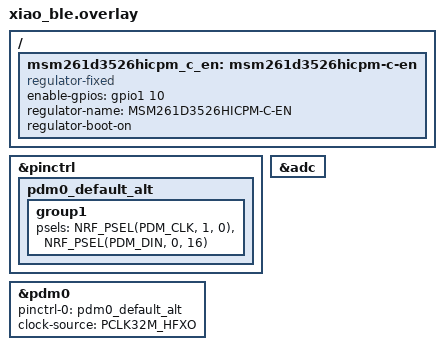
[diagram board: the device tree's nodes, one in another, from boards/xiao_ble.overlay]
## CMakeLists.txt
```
# Helix-Mic Firmware - BLE Audio Streamer for XIAO nRF52840 Sense
cmake_minimum_required(VERSION 3.20.0)

find_package(Zephyr REQUIRED HINTS $ENV{ZEPHYR_BASE})
project(helix-mic)

target_sources(app PRIVATE
    src/main.c
    src/mic.c
    src/transport.c
    src/led.c
)

target_include_directories(app PRIVATE src)
```

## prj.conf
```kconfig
# Helix-Mic Configuration

# Main config — increased for BLE stability
CONFIG_MAIN_STACK_SIZE=4096
CONFIG_SYSTEM_WORKQUEUE_STACK_SIZE=4096

# Bluetooth
CONFIG_BT=y
CONFIG_BT_PERIPHERAL=y
CONFIG_BT_DEVICE_NAME="Helix-Mic"
CONFIG_BT_DEVICE_NAME_DYNAMIC=y
CONFIG_BT_MAX_CONN=1
CONFIG_BT_L2CAP_TX_BUF_COUNT=16
CONFIG_BT_BUF_ACL_TX_SIZE=251
CONFIG_BT_BUF_ACL_RX_SIZE=251
CONFIG_BT_CONN_TX_MAX=16

# BLE stack
CONFIG_BT_RX_STACK_SIZE=4096

# BLE GATT
CONFIG_BT_GATT_DYNAMIC_DB=y
CONFIG_BT_L2CAP_TX_MTU=247

# BLE Security — encrypted link required for audio/battery access
CONFIG_BT_SMP=y
CONFIG_BT_CTLR_DATA_LENGTH_MAX=251
CONFIG_BT_CTLR_PHY_2M=y

# Audio - Zephyr DMIC API (nRF PDM driver)
CONFIG_AUDIO=y
CONFIG_AUDIO_DMIC=y
CONFIG_NRFX_PDM=y

# ADC for battery
CONFIG_ADC=y
CONFIG_ADC_NRFX_SAADC=y

# GPIO for LEDs
CONFIG_GPIO=y

# Logging over USB CDC ACM (board has zephyr,cdc-acm-uart node)
CONFIG_LOG=y
CONFIG_LOG_DEFAULT_LEVEL=3
CONFIG_LOG_MODE_IMMEDIATE=y
CONFIG_CONSOLE=y
CONFIG_PRINTK=y
CONFIG_SERIAL=y
CONFIG_UART_CONSOLE=y
CONFIG_UART_LINE_CTRL=y
CONFIG_LOG_BACKEND_UART=y
CONFIG_USE_SEGGER_RTT=n
CONFIG_LOG_BACKEND_RTT=n

# Ring buffer for audio pipeline
CONFIG_RING_BUFFER=y

# Heap for audio buffers
CONFIG_HEAP_MEM_POOL_SIZE=8192

# Clock
CONFIG_CLOCK_CONTROL_NRF=y

# Power management
CONFIG_PM_DEVICE=y
CONFIG_PM_DEVICE_RUNTIME=y

# Debug
CONFIG_DEBUG_THREAD_INFO=y
CONFIG_THREAD_NAME=y

# Newlib for memcpy etc
CONFIG_NEWLIB_LIBC=y
CONFIG_NEWLIB_LIBC_NANO=n
```

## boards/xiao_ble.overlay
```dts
/* XIAO nRF52840 Sense overlay for Helix-Mic — Zephyr DMIC API */
/* PDM pins per Seeed variant.cpp: CLK=P1.0, DATA=P0.16, PWR=P1.10 */

#include <zephyr/dt-bindings/gpio/gpio.h>

/ {
	msm261d3526hicpm_c_en: msm261d3526hicpm-c-en {
		compatible = "regulator-fixed";
		enable-gpios = <&gpio1 10 GPIO_ACTIVE_HIGH>;
		regulator-name = "MSM261D3526HICPM-C-EN";
		regulator-boot-on;
	};


};

&pinctrl {
	pdm0_default_alt: pdm0_default_alt {
		group1 {
			psels = <NRF_PSEL(PDM_CLK, 1, 0)>,   /* P1.0 = D20 = PDM_CLK */
				<NRF_PSEL(PDM_DIN, 0, 16)>;  /* P0.16 = D21 = PDM_DATA */
		};
	};
};

dmic_dev: &pdm0 {
	status = "okay";
	pinctrl-0 = <&pdm0_default_alt>;
	pinctrl-names = "default";
	clock-source = "PCLK32M_HFXO";
};

&adc {
	status = "okay";
};
```

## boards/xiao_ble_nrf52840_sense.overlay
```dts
/* XIAO nRF52840 Sense overlay for Helix-Mic — NCS v3.2.4 / Zephyr 4.x */
/* Board DTS already sets correct PDM pins (CLK=P1.0, DIN=P0.16) and pinctrl. */

#include <zephyr/dt-bindings/gpio/gpio.h>
#include <zephyr/dt-bindings/adc/adc.h>
#include <zephyr/dt-bindings/adc/nrf-saadc.h>

/ {
	msm261d3526hicpm_c_en: msm261d3526hicpm-c-en {
		compatible = "regulator-fixed";
		enable-gpios = <&gpio1 10 GPIO_ACTIVE_HIGH>;
		regulator-name = "MSM261D3526HICPM-C-EN";
		regulator-boot-on;
	};
};

dmic_dev: &pdm0 {
	status = "okay";
	clock-source = "PCLK32M_HFXO";
};

&adc {
	status = "okay";
	/delete-property/ zephyr,pm-device-runtime-auto;
};
```

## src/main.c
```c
/*
 * Helix-Mic - Main Entry Point
 * 
 * BLE audio streamer for XIAO nRF52840 Sense
 * - PDM mic capture at 16kHz 16-bit mono
 * - Raw PCM streaming over BLE (Opus fallback)
 * - Battery reporting
 */

#include <zephyr/logging/log.h>
LOG_MODULE_REGISTER(main, CONFIG_LOG_DEFAULT_LEVEL);

#include <zephyr/kernel.h>
#include <zephyr/device.h>
#include <zephyr/drivers/adc.h>
#include <zephyr/drivers/gpio.h>
#include <zephyr/devicetree.h>
#include <zephyr/dt-bindings/adc/nrf-saadc.h>
#include <zephyr/sys/ring_buffer.h>

#include "mic.h"
#include "transport.h"
#include "led.h"

/* ─── Battery ADC (matches Tjoms99/xiao_sense_nrf52840_battery_lib) ─── */
#define BATTERY_ADC_CHANNEL  7
#define BATTERY_ADC_GAIN     ADC_GAIN_1_6    /* 0.6V ref × 6 = 3.6V range */
#define BATTERY_ADC_REF      ADC_REF_INTERNAL
#define BATTERY_ADC_RES      12
#define BATTERY_R1           1037  /* kΩ (calibrated from nominal 1MΩ) */
#define BATTERY_R2           510   /* kΩ */
#define BATTERY_MIN_MV       3300
#define BATTERY_MAX_MV       4200

static const struct device *adc_dev = DEVICE_DT_GET(DT_NODELABEL(adc));

/* P0.14 read-enable: ACTIVE_LOW per Seeed schematic */
static const struct gpio_dt_spec bat_read_en = {
    .port = DEVICE_DT_GET(DT_NODELABEL(gpio0)),
    .pin = 14,
    .dt_flags = GPIO_ACTIVE_LOW,
};

static struct adc_channel_cfg adc_cfg = {
    .gain             = BATTERY_ADC_GAIN,
    .reference        = BATTERY_ADC_REF,
    .acquisition_time = ADC_ACQ_TIME(ADC_ACQ_TIME_MICROSECONDS, 40),
    .channel_id       = BATTERY_ADC_CHANNEL,
#if defined(CONFIG_ADC_NRFX_SAADC)
    .input_positive   = NRF_SAADC_AIN7,
#endif
};

static int16_t adc_buffer;
static struct adc_sequence adc_seq = {
    .channels    = BIT(BATTERY_ADC_CHANNEL),
    .buffer      = &adc_buffer,
    .buffer_size = sizeof(adc_buffer),
    .resolution  = BATTERY_ADC_RES,
};

/* Forward declarations */
static void audio_frame_handler(int16_t *buf, size_t num_samples);
static void connection_changed(bool connected);
static void on_connect_start_mic(void);
static int init_battery_adc(void);
/* Reads the battery: returns percent (0-100) or 0xFF on failure.
 * Writes the measured millivolts into *out_mv on success (0 on failure). */
static uint8_t read_battery_level(uint16_t *out_mv);

/* Track mic state for fallback start */
static volatile bool mic_running = false;

/* Ring buffer for decoupling PDM callback from BLE sends */
#define RING_BUF_PACKETS 16  /* ~1.6s buffer at 100ms frames */
#define PCM_FRAME_BYTES  (1600 * sizeof(int16_t))  /* 3200 bytes per 100ms frame */

static uint8_t ring_buf_data[RING_BUF_PACKETS * PCM_FRAME_BYTES];
static struct ring_buf audio_ring_buf;

/* Pusher thread — drains ring buffer into BLE notifications */
K_THREAD_STACK_DEFINE(pusher_stack, 4096);
static struct k_thread pusher_thread;

static uint16_t pusher_seq = 0;
#define CHUNK_SIZE 240

static void pusher_entry(void *p1, void *p2, void *p3)
{
    ARG_UNUSED(p1);
    ARG_UNUSED(p2);
    ARG_UNUSED(p3);

    uint8_t chunk[CHUNK_SIZE];

    while (1) {
        if (!transport_is_connected() || ring_buf_size_get(&audio_ring_buf) == 0) {
            k_sleep(K_MSEC(5));
            continue;
        }

        size_t got = ring_buf_get(&audio_ring_buf, chunk, CHUNK_SIZE);
        if (got > 0) {
            int ret;
            int retries = 0;
            do {
                ret = transport_send_audio(chunk, got, pusher_seq, 0x01);
                if (ret == -ENOBUFS || ret == -ENOMEM) {
                    k_sleep(K_MSEC(2));
                    retries++;
                }
            } while ((ret == -ENOBUFS || ret == -ENOMEM) && retries < 20);

            if (ret == 0) {
                pusher_seq++;
                if (pusher_seq % 500 == 1) {
                    LOG_INF("Audio pusher: sent %u packets, ring=%u",
                            pusher_seq, ring_buf_size_get(&audio_ring_buf));
                }
                /* Pace: ~7ms between 240-byte chunks = ~140 chunks/sec
                 * 13 chunks per 100ms frame = exactly real-time */
                k_sleep(K_MSEC(7));
            } else if (pusher_seq < 5) {
                LOG_WRN("Audio send failed: %d (seq=%u)", ret, pusher_seq);
            }
        }
    }
}

/* Main thread */
int main(void)
{
    int ret;
    
    LOG_INF("Helix-Mic starting...");
    
    /* Initialize LED first for boot indication */
    ret = led_init();
    if (ret < 0) {
        LOG_WRN("LED init failed: %d", ret);
    } else {
        led_set_state(LED_STATE_BOOT);
    }
    
    /* Initialize subsystems */
    ret = mic_init();
    if (ret < 0) {
        LOG_ERR("Mic init failed: %d", ret);
        return ret;
    }
    

    
    ret = transport_init();
    if (ret < 0) {
        LOG_ERR("Transport init failed: %d", ret);
        return ret;
    }
    
    ret = init_battery_adc();
    if (ret < 0) {
        LOG_WRN("Battery ADC init failed: %d", ret);
    }
    
    /* Initialize audio ring buffer and pusher thread */
    ring_buf_init(&audio_ring_buf, sizeof(ring_buf_data), ring_buf_data);
    k_thread_create(&pusher_thread, pusher_stack,
                    K_THREAD_STACK_SIZEOF(pusher_stack),
                    pusher_entry, NULL, NULL, NULL,
                    K_PRIO_PREEMPT(7), 0, K_NO_WAIT);
    k_thread_name_set(&pusher_thread, "pusher");

    /* Set callbacks */
    mic_set_frame_callback(audio_frame_handler);
    transport_set_conn_callback(connection_changed);
    transport_set_mic_start(on_connect_start_mic);
    
    /* Start BLE advertising */
    ret = transport_start_advertising();
    if (ret < 0) {
        LOG_ERR("Advertising start failed: %d", ret);
        return ret;
    }
    
    /* Boot blinks should be done by now, switch to advertising */
    led_set_state(LED_STATE_ADVERTISING);
    
    LOG_INF("Helix-Mic ready - waiting for connection");
    
    /* Main loop: poll battery every 5s while connected. LED state transitions
     * are handled directly by connection_changed() callbacks. The regular
     * battery notification also serves as a BLE link keepalive when no
     * audio is streaming. */
    while (1) {
        if (transport_is_connected()) {
            uint16_t mv = 0;
            uint8_t level = read_battery_level(&mv);
            transport_update_battery(level, mv);
            if (level == 0xFF) {
                LOG_WRN("Battery read failed");
            } else {
                LOG_INF("Battery: %u%% (%u mV)", level, mv);
            }
        }
        k_sleep(K_SECONDS(5));
    }
    
    return 0;
}

static void audio_frame_handler(int16_t *buf, size_t num_samples)
{
    if (!transport_is_connected()) {
        return;
    }

    led_notify_audio();

    size_t bytes = num_samples * sizeof(int16_t);
    int written = ring_buf_put(&audio_ring_buf, (uint8_t *)buf, bytes);
    if (written != (int)bytes) {
        LOG_WRN("Ring buf full, dropped %zu bytes", bytes - (size_t)written);
    }
}

static void on_connect_start_mic(void)
{
    int ret;
    
    if (mic_running) {
        LOG_INF("Mic already running, skipping start");
        return;
    }
    
    LOG_INF("Starting audio stream...");
    ret = mic_start();
    if (ret < 0) {
        LOG_ERR("=== MIC START FAILED === error code: %d", ret);
        switch (ret) {
        case -ENODEV:
            LOG_ERR("  Reason: PDM device not found/not ready");
            break;
        case -EINVAL:
            LOG_ERR("  Reason: Invalid PDM configuration");
            break;
        case -EIO:
            LOG_ERR("  Reason: I/O error during PDM start");
            break;
        case -EBUSY:
            LOG_ERR("  Reason: PDM device busy");
            break;
        default:
            LOG_ERR("  Reason: Unknown (check nrfx_pdm error codes)");
            break;
        }
    } else {
        mic_running = true;
        LOG_INF("Mic started successfully");
    }
}

/* Delayed work to set LED to ADVERTISING after the red disconnect flash. */
static void led_advertising_work_handler(struct k_work *work)
{
    led_set_state(LED_STATE_ADVERTISING);
}
static K_WORK_DELAYABLE_DEFINE(led_advertising_work, led_advertising_work_handler);

static void connection_changed(bool connected)
{
    if (connected) {
        LOG_INF("=== CONNECTION ESTABLISHED ===");
        /* Cancel any pending advertising-LED transition from a previous disconnect */
        k_work_cancel_delayable(&led_advertising_work);
        led_set_state(LED_STATE_CONNECTED_IDLE);
    } else {
        LOG_INF("=== CLIENT DISCONNECTED === stopping audio stream");
        /* Only run the full teardown once — this callback can fire twice
         * (once from audio_ccc_changed on unsubscribe, once from the BT
         * disconnected() callback). */
        if (!mic_running) {
            LOG_INF("connection_changed(false) — already torn down, skipping");
            /* Still ensure LED is advertising even if we skip teardown */
            k_work_reschedule(&led_advertising_work, K_MSEC(250));
            return;
        }
        int ret = mic_stop();
        if (ret < 0) {
            LOG_ERR("Mic stop failed: %d", ret);
        } else {
            LOG_INF("Mic stopped cleanly");
        }
        mic_running = false;

        /* Flush stale audio from the ring buffer so the next connection
         * doesn't start with leftover data from the previous session. */
        ring_buf_reset(&audio_ring_buf);
        pusher_seq = 0;

        /* Brief red flash, then schedule advertising LED at 250ms via
         * delayable work (don't block the system workqueue with k_sleep). */
        led_set_state(LED_STATE_DISCONNECTED);
        k_work_reschedule(&led_advertising_work, K_MSEC(250));
        LOG_INF("State reset, advertising again");
    }
}

static int init_battery_adc(void)
{
    int ret;

    if (!device_is_ready(adc_dev)) {
        LOG_ERR("ADC device not ready");
        return -ENODEV;
    }

    ret = adc_channel_setup(adc_dev, &adc_cfg);
    if (ret < 0) {
        LOG_ERR("ADC channel setup failed: %d", ret);
        return ret;
    }
    LOG_INF("ADC channel 7 configured");

    /* Enable battery voltage divider — GPIO_ACTIVE_LOW so logical 1 = pin LOW */
    if (!device_is_ready(bat_read_en.port)) {
        LOG_ERR("GPIO0 not ready for battery enable");
        return -ENODEV;
    }

    ret = gpio_pin_configure_dt(&bat_read_en, GPIO_OUTPUT_ACTIVE);
    if (ret < 0) {
        LOG_ERR("Battery read-enable pin config failed: %d", ret);
        return ret;
    }

    return 0;
}

static uint8_t read_battery_level(uint16_t *out_mv)
{
    if (out_mv) *out_mv = 0;

    int ret = adc_read(adc_dev, &adc_seq);
    if (ret < 0) {
        LOG_WRN("adc_read failed: %d", ret);
        return 0xFF;
    }

    /* Convert raw → millivolts at the ADC pin */
    int32_t adc_mv = adc_buffer;
    ret = adc_raw_to_millivolts(adc_ref_internal(adc_dev),
                                BATTERY_ADC_GAIN, BATTERY_ADC_RES, &adc_mv);
    if (ret < 0) {
        return 0xFF;
    }

    /* Scale through voltage divider to get actual battery voltage */
    uint32_t bat_mv = (uint32_t)adc_mv * (BATTERY_R1 + BATTERY_R2) / BATTERY_R2;

    if (out_mv) *out_mv = (uint16_t)bat_mv;

    if (bat_mv <= BATTERY_MIN_MV) return 0;
    if (bat_mv >= BATTERY_MAX_MV) return 100;
    return (uint8_t)(((bat_mv - BATTERY_MIN_MV) * 100) / (BATTERY_MAX_MV - BATTERY_MIN_MV));
}
```

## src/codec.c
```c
/*
 * Helix-Mic - Audio Codec
 * 
 * Falls back to raw PCM if Opus not available in SDK
 */

#include <zephyr/logging/log.h>
LOG_MODULE_REGISTER(codec, CONFIG_LOG_DEFAULT_LEVEL);

#include "codec.h"

/* Opus not readily available in base Zephyr - use raw PCM for now */
/* TODO: Integrate Opus from external lib when available */

static bool use_opus = false;
static uint16_t encode_seq = 0;

int codec_init(void)
{
    /* Check for Opus library - for now assume not available */
    use_opus = false;
    
    LOG_WRN("Opus not available - using raw PCM output");
    return 0;
}

bool codec_is_opus(void)
{
    return use_opus;
}

int codec_encode(const int16_t *samples, size_t sample_count,
                 struct encoded_frame *out)
{
    out->seq_num = encode_seq++;
    out->flags = 0x01; /* Flag: 0x01 = raw PCM, 0x00 = Opus */
    
    if (use_opus) {
        /* Placeholder for Opus encoding */
        /* Would call opus_encode() here */
        out->len = 0;
        return -1;
    } else {
        /* Raw PCM passthrough - chunk into smaller packets */
        /* BLE has MTU limits, so we send ~80 bytes max payload */
        size_t bytes_to_copy = sample_count * sizeof(int16_t);
        
        if (bytes_to_copy > MAX_ENCODED_SIZE) {
            bytes_to_copy = MAX_ENCODED_SIZE;
        }
        
        memcpy(out->data, samples, bytes_to_copy);
        out->len = bytes_to_copy;
        
        /* Mark as PCM in flags */
        out->flags |= 0x01;
        
        return 0;
    }
}
```

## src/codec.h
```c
/*
 * Helix-Mic - Audio Codec (Opus or PCM fallback)
 */

#ifndef CODEC_H
#define CODEC_H

#include <zephyr/kernel.h>
#include <stdint.h>
#include <stddef.h>

#define OPUS_FRAME_SIZE  40   /* ~20ms at 16kbps */
#define MAX_ENCODED_SIZE 80   /* Max encoded frame size */

struct encoded_frame {
    uint16_t seq_num;
    uint8_t flags;
    uint8_t data[MAX_ENCODED_SIZE];
    size_t len;
};

/* Initialize codec */
int codec_init(void);

/* Encode audio samples */
int codec_encode(const int16_t *samples, size_t sample_count,
                 struct encoded_frame *out);

/* Check if Opus is available */
bool codec_is_opus(void);

#endif /* CODEC_H */
```

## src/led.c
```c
/*
 * Helix-Mic - LED Status Indicators
 *
 * RGB LED on XIAO nRF52840 Sense (active-low):
 *   led0 = Red   (P0.26)
 *   led1 = Green (P0.30)
 *   led2 = Blue  (P0.06)
 */

#include <zephyr/logging/log.h>
LOG_MODULE_REGISTER(led, CONFIG_LOG_DEFAULT_LEVEL);

#include "led.h"
#include <zephyr/drivers/gpio.h>

/* LED GPIO specs from devicetree aliases */
static const struct gpio_dt_spec led_red   = GPIO_DT_SPEC_GET(DT_ALIAS(led0), gpios);
static const struct gpio_dt_spec led_green = GPIO_DT_SPEC_GET(DT_ALIAS(led1), gpios);
static const struct gpio_dt_spec led_blue  = GPIO_DT_SPEC_GET(DT_ALIAS(led2), gpios);

static enum led_state current_state = LED_STATE_OFF;
static int64_t last_audio_time;

/* Timer for blink/pulse patterns */
static void led_timer_handler(struct k_timer *timer);
K_TIMER_DEFINE(led_timer, led_timer_handler, NULL);

/* Boot animation state */
static uint8_t boot_blink_count;

/* ---- Low-level helpers ---- */

static inline void all_off(void)
{
    gpio_pin_set_dt(&led_red, 0);
    gpio_pin_set_dt(&led_green, 0);
    gpio_pin_set_dt(&led_blue, 0);
}

static inline void set_red(int on)   { gpio_pin_set_dt(&led_red, on); }
static inline void set_green(int on) { gpio_pin_set_dt(&led_green, on); }
static inline void set_blue(int on)  { gpio_pin_set_dt(&led_blue, on); }

/* ---- Timer callback (runs in ISR context) ---- */

static bool toggle;

static void led_timer_handler(struct k_timer *timer)
{
    toggle = !toggle;

    switch (current_state) {
    case LED_STATE_BOOT:
        /* 2 quick blue blinks: on 100ms, off 100ms x2, then done */
        if (boot_blink_count < 4) {
            set_blue(boot_blink_count % 2 == 0 ? 1 : 0);
            boot_blink_count++;
        } else {
            all_off();
            /* Boot done — transition to advertising */
            current_state = LED_STATE_ADVERTISING;
            k_timer_start(&led_timer, K_MSEC(500), K_MSEC(500));
        }
        break;

    case LED_STATE_ADVERTISING:
        /* Slow blue pulse: 500ms on, 500ms off */
        set_blue(toggle ? 1 : 0);
        break;

    case LED_STATE_CONNECTED_IDLE:
        /* Slow green blink: 500ms on, 500ms off */
        set_green(toggle ? 1 : 0);
        break;

    case LED_STATE_CONNECTED_AUDIO:
        /* Solid green — check if audio stopped (>300ms no frames) */
        if (k_uptime_get() - last_audio_time > 300) {
            current_state = LED_STATE_CONNECTED_IDLE;
            all_off();
            /* Timer already running at 500ms for idle blink */
            k_timer_start(&led_timer, K_MSEC(500), K_MSEC(500));
        }
        break;

    case LED_STATE_DISCONNECTED:
        /* Red was flashed — turn off and stop */
        all_off();
        current_state = LED_STATE_OFF;
        k_timer_stop(&led_timer);
        break;

    default:
        break;
    }
}

/* ---- Public API ---- */

int led_init(void)
{
    int ret;

    if (!gpio_is_ready_dt(&led_red) ||
        !gpio_is_ready_dt(&led_green) ||
        !gpio_is_ready_dt(&led_blue)) {
        LOG_ERR("LED GPIO not ready");
        return -ENODEV;
    }

    ret = gpio_pin_configure_dt(&led_red, GPIO_OUTPUT_INACTIVE);
    if (ret < 0) return ret;
    ret = gpio_pin_configure_dt(&led_green, GPIO_OUTPUT_INACTIVE);
    if (ret < 0) return ret;
    ret = gpio_pin_configure_dt(&led_blue, GPIO_OUTPUT_INACTIVE);
    if (ret < 0) return ret;

    all_off();
    LOG_INF("LED initialized");
    return 0;
}

void led_set_state(enum led_state state)
{
    k_timer_stop(&led_timer);
    all_off();
    toggle = false;
    current_state = state;

    switch (state) {
    case LED_STATE_OFF:
        /* Nothing to do */
        break;

    case LED_STATE_BOOT:
        /* 2 quick blue blinks: 100ms intervals */
        boot_blink_count = 0;
        set_blue(1);
        boot_blink_count = 1;
        k_timer_start(&led_timer, K_MSEC(100), K_MSEC(100));
        break;

    case LED_STATE_ADVERTISING:
        set_blue(1);
        k_timer_start(&led_timer, K_MSEC(500), K_MSEC(500));
        break;

    case LED_STATE_CONNECTED_AUDIO:
        set_green(1);
        last_audio_time = k_uptime_get();
        /* Check periodically if audio stops */
        k_timer_start(&led_timer, K_MSEC(500), K_MSEC(500));
        break;

    case LED_STATE_CONNECTED_IDLE:
        set_green(1);
        k_timer_start(&led_timer, K_MSEC(500), K_MSEC(500));
        break;

    case LED_STATE_DISCONNECTED:
        /* Brief red flash (200ms) */
        set_red(1);
        k_timer_start(&led_timer, K_MSEC(200), K_NO_WAIT);
        break;
    }
}

void led_notify_audio(void)
{
    last_audio_time = k_uptime_get();

    /* If we were idle, switch to audio state */
    if (current_state == LED_STATE_CONNECTED_IDLE) {
        k_timer_stop(&led_timer);
        all_off();
        set_green(1);
        current_state = LED_STATE_CONNECTED_AUDIO;
        k_timer_start(&led_timer, K_MSEC(500), K_MSEC(500));
    }
}
```

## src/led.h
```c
/*
 * Helix-Mic - LED Status Indicators
 */

#ifndef HELIX_LED_H
#define HELIX_LED_H

#include <zephyr/kernel.h>

/* LED states */
enum led_state {
    LED_STATE_OFF,              /* All off */
    LED_STATE_BOOT,             /* Brief blue blinks on startup */
    LED_STATE_ADVERTISING,      /* Slow blue pulse (500ms on/off) */
    LED_STATE_CONNECTED_AUDIO,  /* Solid green */
    LED_STATE_CONNECTED_IDLE,   /* Slow green blink */
    LED_STATE_DISCONNECTED,     /* Brief red flash, then off */
};

/* Initialize LED GPIOs */
int led_init(void);

/* Set the current LED state */
void led_set_state(enum led_state state);

/* Call from audio path to signal activity */
void led_notify_audio(void);

#endif /* HELIX_LED_H */
```

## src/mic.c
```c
/*
 * Helix-Mic - PDM Microphone Capture using Zephyr DMIC API
 *
 * Uses Zephyr's standard DMIC driver with k_mem_slab for buffer management.
 * Mic enable (P1.10) is handled by device tree regulator-fixed with regulator-boot-on.
 */

#include <zephyr/logging/log.h>
LOG_MODULE_REGISTER(mic, CONFIG_LOG_DEFAULT_LEVEL);

#include "mic.h"

#include <zephyr/audio/dmic.h>
#include <zephyr/drivers/gpio.h>

/* Buffer management — DMIC driver allocates from this slab */
#define BYTES_PER_SAMPLE  sizeof(int16_t)
#define BLOCK_SIZE        (BYTES_PER_SAMPLE * SAMPLES_PER_FRAME * NUM_CHANNELS)
#define BLOCK_COUNT       4
K_MEM_SLAB_DEFINE_STATIC(mic_mem_slab, BLOCK_SIZE, BLOCK_COUNT, 4);

/* Mic reader thread */
#define MIC_THREAD_STACK_SIZE 2048
#define MIC_THREAD_PRIORITY   K_PRIO_PREEMPT(5)
K_THREAD_STACK_DEFINE(mic_thread_stack, MIC_THREAD_STACK_SIZE);
static struct k_thread mic_thread_data;

static const struct device *dmic;
static volatile mic_frame_cb_t frame_callback;
static volatile bool mic_running;

/* Read timeout in ms */
#define READ_TIMEOUT_MS 1000


static void mic_reader_entry(void *p1, void *p2, void *p3)
{
	ARG_UNUSED(p1);
	ARG_UNUSED(p2);
	ARG_UNUSED(p3);

	void *buffer;
	uint32_t size;
	int ret;

	LOG_INF("Mic reader thread started");

	while (mic_running) {
		ret = dmic_read(dmic, 0, &buffer, &size, READ_TIMEOUT_MS);
		if (ret < 0) {
			if (mic_running) {
				LOG_ERR("dmic_read failed: %d", ret);
			}
			continue;
		}

		if (frame_callback && size > 0) {
			size_t num_samples = size / BYTES_PER_SAMPLE;
			frame_callback((int16_t *)buffer, num_samples);
		}

		k_mem_slab_free(&mic_mem_slab, buffer);
	}

	LOG_INF("Mic reader thread exiting");
}

int mic_init(void)
{
	dmic = DEVICE_DT_GET(DT_NODELABEL(dmic_dev));
	if (!device_is_ready(dmic)) {
		LOG_ERR("DMIC device not ready");
		return -ENODEV;
	}

	LOG_INF("DMIC device initialized (Zephyr DMIC API)");
	return 0;
}

int mic_start(void)
{
	int ret;

	if (mic_running) {
		LOG_WRN("Mic already running");
		return 0;
	}

	/* Force mic power on — regulator-fixed may not work on all boards */
	const struct device *gpio1 = DEVICE_DT_GET(DT_NODELABEL(gpio1));
	if (device_is_ready(gpio1)) {
		gpio_pin_configure(gpio1, 10, GPIO_OUTPUT_ACTIVE);
		gpio_pin_set(gpio1, 10, 1);
		LOG_INF("Mic power P1.10 forced HIGH");
		k_sleep(K_MSEC(50)); /* Let mic stabilize */
	} else {
		LOG_ERR("GPIO1 not ready — mic power may not be enabled!");
	}

	struct pcm_stream_cfg stream = {
		.pcm_rate  = SAMPLE_RATE,
		.pcm_width = SAMPLE_BITS,
		.block_size = BLOCK_SIZE,
		.mem_slab  = &mic_mem_slab,
	};

	struct dmic_cfg cfg = {
		.io = {
			.min_pdm_clk_freq = 1000000,
			.max_pdm_clk_freq = 3500000,
			.min_pdm_clk_dc   = 40,
			.max_pdm_clk_dc   = 60,
		},
		.streams = &stream,
		.channel = {
			.req_num_streams = 1,
			.req_num_chan = NUM_CHANNELS,
			.req_chan_map_lo = dmic_build_channel_map(0, 0, PDM_CHAN_LEFT),
		},
	};

	ret = dmic_configure(dmic, &cfg);
	if (ret < 0) {
		LOG_ERR("dmic_configure failed: %d", ret);
		return ret;
	}

	ret = dmic_trigger(dmic, DMIC_TRIGGER_START);
	if (ret < 0) {
		LOG_ERR("dmic_trigger START failed: %d", ret);
		return ret;
	}

	mic_running = true;

	/* Spawn reader thread */
	k_thread_create(&mic_thread_data, mic_thread_stack,
			K_THREAD_STACK_SIZEOF(mic_thread_stack),
			mic_reader_entry, NULL, NULL, NULL,
			MIC_THREAD_PRIORITY, 0, K_NO_WAIT);
	k_thread_name_set(&mic_thread_data, "mic_reader");

	LOG_INF("DMIC capture started (%d Hz, %d-bit, %d ms frames)",
		SAMPLE_RATE, SAMPLE_BITS, FRAME_SIZE_MS);
	return 0;
}

int mic_stop(void)
{
	int ret;

	if (!mic_running) {
		return 0;
	}

	mic_running = false;

	ret = dmic_trigger(dmic, DMIC_TRIGGER_STOP);
	if (ret < 0) {
		LOG_ERR("dmic_trigger STOP failed: %d", ret);
		return ret;
	}

	/* Wait for reader thread to exit */
	k_thread_join(&mic_thread_data, K_MSEC(2000));

	LOG_INF("DMIC capture stopped");
	return 0;
}

void mic_set_frame_callback(mic_frame_cb_t cb)
{
	frame_callback = cb;
}
```

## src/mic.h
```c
/*
 * Helix-Mic - Header for PDM microphone capture (Zephyr DMIC API)
 */

#ifndef HELIX_MIC_H
#define HELIX_MIC_H

#include <zephyr/kernel.h>
#include <stdint.h>
#include <stddef.h>

#define SAMPLE_RATE       16000
#define SAMPLE_BITS       16
#define NUM_CHANNELS      1
#define FRAME_SIZE_MS     100  /* 100ms frames = 1600 samples at 16kHz */
#define SAMPLES_PER_FRAME (SAMPLE_RATE * FRAME_SIZE_MS / 1000)

/* Audio frame callback — receives raw PCM buffer pointer (valid only during call) */
typedef void (*mic_frame_cb_t)(int16_t *buf, size_t num_samples);

/* Initialize DMIC device */
int mic_init(void);

/* Start audio capture */
int mic_start(void);

/* Stop audio capture */
int mic_stop(void);

/* Set audio frame callback */
void mic_set_frame_callback(mic_frame_cb_t cb);

#endif /* HELIX_MIC_H */
```

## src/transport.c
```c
/*
 * Helix-Mic - BLE Transport Implementation
 *
 * Dynamic GATT service with audio streaming and battery notifications.
 * Android client drives link negotiation (MTU, PHY, DLE) to avoid
 * races on NCS v3.2.4.
 */

#include <zephyr/logging/log.h>
LOG_MODULE_REGISTER(transport, CONFIG_LOG_DEFAULT_LEVEL);

#include "transport.h"

#include <zephyr/bluetooth/bluetooth.h>
#include <zephyr/bluetooth/conn.h>
#include <zephyr/bluetooth/uuid.h>
#include <zephyr/bluetooth/gatt.h>
#include <string.h>

/* Zephyr 4.x renamed BT_LE_ADV_OPT_CONNECTABLE → BT_LE_ADV_OPT_CONN
 * and removed the BT_LE_ADV_CONN convenience macro. */
#ifndef BT_LE_ADV_CONN
#define BT_LE_ADV_CONN BT_LE_ADV_PARAM(BT_LE_ADV_OPT_CONN, \
                                        BT_GAP_ADV_FAST_INT_MIN_2, \
                                        BT_GAP_ADV_FAST_INT_MAX_2, \
                                        NULL)
#endif

/* ─── UUIDs ─────────────────────────────────────────────────────────── */

#define HELIX_SVC_UUID_VAL \
    BT_UUID_128_ENCODE(0x917649A0, 0xD98E, 0x11E5, 0x9EEC, 0x0002A5D5C51B)
#define HELIX_AUDIO_UUID_VAL \
    BT_UUID_128_ENCODE(0x917649B0, 0xD98E, 0x11E5, 0x9EEC, 0x0002A5D5C51B)
#define HELIX_BATTERY_UUID_VAL \
    BT_UUID_128_ENCODE(0x917649A2, 0xD98E, 0x11E5, 0x9EEC, 0x0002A5D5C51B)

static struct bt_uuid_128 helix_svc_uuid    = BT_UUID_INIT_128(HELIX_SVC_UUID_VAL);
static struct bt_uuid_128 helix_audio_uuid   = BT_UUID_INIT_128(HELIX_AUDIO_UUID_VAL);
static struct bt_uuid_128 helix_battery_uuid = BT_UUID_INIT_128(HELIX_BATTERY_UUID_VAL);

/* ─── State ─────────────────────────────────────────────────────────── */

static struct bt_conn *current_conn;
static volatile bool is_connected;
static transport_conn_cb_t conn_callback;
static void (*mic_start_fn)(void);

/* ─── Deferred work items (BT callbacks → system workqueue) ─────────── */
/*
 * BT GATT/conn callbacks run in the BT RX thread context.
 * Calling dmic_configure/dmic_trigger/k_thread_join/k_sleep from there
 * causes hard faults or deadlocks.  Defer to the system workqueue.
 */
static struct k_work mic_start_work;
static struct k_work mic_stop_work;

static void mic_start_handler(struct k_work *work)
{
    if (mic_start_fn) {
        mic_start_fn();
    }
    if (conn_callback) {
        conn_callback(true);
    }
}

static void mic_stop_handler(struct k_work *work)
{
    if (conn_callback) {
        conn_callback(false);
    }
}

/* Audio packet buffer: 3-byte header + up to 700 bytes payload */
static uint8_t audio_pkt[703];
/* [0] percent (0-100 or 0xFF = unknown), [1..2] millivolts LE */
static uint8_t battery_packet[3] = { 0xFF, 0, 0 };

/* Negotiated MTU (default minimum, updated after exchange) */
static uint16_t current_mtu = 23;

/* Track audio subscription state */
static volatile bool audio_subscribed = false;

/* ─── CCC callbacks ─────────────────────────────────────────────────── */

static void audio_ccc_changed(const struct bt_gatt_attr *attr, uint16_t value)
{
    LOG_INF("Audio notifications %s", value ? "enabled" : "disabled");
    if (value == BT_GATT_CCC_NOTIFY) {
        audio_subscribed = true;
        k_work_submit(&mic_start_work);
    } else {
        audio_subscribed = false;
        k_work_submit(&mic_stop_work);
    }
}

static void battery_ccc_changed(const struct bt_gatt_attr *attr, uint16_t value)
{
    LOG_INF("Battery notifications %s", value ? "enabled" : "disabled");
}

/* ─── Battery read handler ──────────────────────────────────────────── */

static ssize_t read_battery(struct bt_conn *conn,
                            const struct bt_gatt_attr *attr,
                            void *buf, uint16_t len, uint16_t offset)
{
    return bt_gatt_attr_read(conn, attr, buf, len, offset,
                             battery_packet, sizeof(battery_packet));
}

/* ─── Dynamic GATT service ──────────────────────────────────────────── */

/* Attribute table for the Helix service (registered dynamically).
 * All characteristics require an encrypted link — unauthenticated
 * (Just Works) pairing provides AES-CCM encryption against passive
 * eavesdropping.  Bonding persists the keys for seamless reconnect. */
static struct bt_gatt_attr helix_attrs[] = {
    /* [0] Primary Service */
    BT_GATT_PRIMARY_SERVICE(&helix_svc_uuid),

    /* [1] Audio Characteristic Declaration */
    BT_GATT_CHARACTERISTIC(&helix_audio_uuid.uuid,
                           BT_GATT_CHRC_NOTIFY,
                           BT_GATT_PERM_NONE,
                           NULL, NULL, NULL),
    /* [2] is the auto-generated value attr from the macro above */

    /* [3] Audio CCC — require encrypted link to subscribe */
    BT_GATT_CCC(audio_ccc_changed,
                 BT_GATT_PERM_READ_ENCRYPT | BT_GATT_PERM_WRITE_ENCRYPT),

    /* [4] Battery Characteristic Declaration */
    BT_GATT_CHARACTERISTIC(&helix_battery_uuid.uuid,
                           BT_GATT_CHRC_READ | BT_GATT_CHRC_NOTIFY,
                           BT_GATT_PERM_READ_ENCRYPT,
                           read_battery, NULL, NULL),
    /* [5] is the auto-generated value attr */

    /* [6] Battery CCC */
    BT_GATT_CCC(battery_ccc_changed,
                 BT_GATT_PERM_READ_ENCRYPT | BT_GATT_PERM_WRITE_ENCRYPT),
};

static struct bt_gatt_service helix_svc = BT_GATT_SERVICE(helix_attrs);

/*
 * Attribute indices (after macro expansion):
 *   [0] Primary Service
 *   [1] Audio Char Declaration
 *   [2] Audio Char Value       <-- notify target for audio
 *   [3] Audio CCC
 *   [4] Battery Char Declaration
 *   [5] Battery Char Value     <-- notify target for battery
 *   [6] Battery CCC
 */
#define AUDIO_ATTR_IDX   2
#define BATTERY_ATTR_IDX 5

/* ─── Advertising ───────────────────────────────────────────────────── */

static const struct bt_data ad[] = {
    BT_DATA_BYTES(BT_DATA_FLAGS, (BT_LE_AD_GENERAL | BT_LE_AD_NO_BREDR)),
    BT_DATA(BT_DATA_NAME_COMPLETE, "Helix-Mic", 9),
};

static const struct bt_data sd[] = {
    BT_DATA_BYTES(BT_DATA_UUID128_ALL, HELIX_SVC_UUID_VAL),
};

/* ─── Connection callbacks ──────────────────────────────────────────── */

static void connected(struct bt_conn *conn, uint8_t err)
{
    if (err) {
        LOG_ERR("Connection failed (err %u)", err);
        return;
    }

    LOG_INF("Connected");

    current_conn = bt_conn_ref(conn);
    is_connected = true;

    /* Request a longer supervision timeout so the link survives idle periods
     * (screen off, app backgrounded). Without this the Android side often
     * disconnects with GATT_CONN_TIMEOUT when no data is flowing.
     * interval 7.5-40ms, latency 0 (no slave latency), timeout 6 seconds. */
    struct bt_le_conn_param param = {
        .interval_min = 6,     /* 7.5ms */
        .interval_max = 32,    /* 40ms */
        .latency      = 0,
        .timeout      = 600,   /* 6000ms (6s) */
    };
    int up_err = bt_conn_le_param_update(conn, &param);
    if (up_err) {
        LOG_WRN("Connection param update failed: %d", up_err);
    }

    LOG_INF("Waiting for client to subscribe before streaming");
}

static void disconnected(struct bt_conn *conn, uint8_t reason)
{
    LOG_INF("Disconnected (reason %u)", reason);

    if (current_conn) {
        bt_conn_unref(current_conn);
        current_conn = NULL;
    }

    is_connected = false;
    audio_subscribed = false;
    current_mtu = 23;

    k_work_submit(&mic_stop_work);

    /* Restart advertising automatically */
    int err = bt_le_adv_start(BT_LE_ADV_CONN, ad, ARRAY_SIZE(ad),
                              sd, ARRAY_SIZE(sd));
    if (err) {
        LOG_ERR("Re-advertising failed: %d", err);
    } else {
        LOG_INF("Advertising restarted");
    }
}

BT_CONN_CB_DEFINE(conn_callbacks) = {
    .connected    = connected,
    .disconnected = disconnected,
};

/* ─── Public API ────────────────────────────────────────────────────── */

int transport_init(void)
{
    int err;

    err = bt_enable(NULL);
    if (err) {
        LOG_ERR("Bluetooth enable failed: %d", err);
        return err;
    }

    LOG_INF("Bluetooth initialized");

    /* Register GATT service dynamically */
    err = bt_gatt_service_register(&helix_svc);
    if (err) {
        LOG_ERR("GATT service register failed: %d", err);
        return err;
    }

    LOG_INF("Helix GATT service registered");

    /* Initialize deferred work items for BT callback → workqueue */
    k_work_init(&mic_start_work, mic_start_handler);
    k_work_init(&mic_stop_work, mic_stop_handler);

    return 0;
}

int transport_start_advertising(void)
{
    int err = bt_le_adv_start(BT_LE_ADV_CONN, ad, ARRAY_SIZE(ad),
                              sd, ARRAY_SIZE(sd));
    if (err) {
        LOG_ERR("Advertising failed: %d", err);
        return err;
    }

    LOG_INF("Advertising started");
    return 0;
}

int transport_send_audio(const uint8_t *data, size_t len,
                         uint16_t seq, uint8_t flags)
{
    if (!is_connected || !current_conn) {
        return -ENOTCONN;
    }
    
    /* Don't send until client has subscribed to audio notifications */
    if (!audio_subscribed) {
        return -EAGAIN;
    }

    /* Refresh MTU — the client drives the exchange, so current_mtu
     * may still be the default 23 from init.  bt_gatt_get_mtu() is
     * cheap (just reads the conn struct). */
    uint16_t live_mtu = bt_gatt_get_mtu(current_conn);
    if (live_mtu != current_mtu) {
        LOG_INF("MTU updated: %u → %u", current_mtu, live_mtu);
        current_mtu = live_mtu;
    }

    /* Build packet: [seq_num:2][flags:1][payload] */
    size_t total = 3 + len;
    if (total > sizeof(audio_pkt)) {
        total = sizeof(audio_pkt);
        len = total - 3;
    }

    /* Clamp to negotiated MTU (ATT header = 3 bytes) */
    uint16_t max_payload = current_mtu - 3;
    if (total > max_payload) {
        total = max_payload;
        len = total - 3;
    }

    audio_pkt[0] = seq & 0xFF;
    audio_pkt[1] = (seq >> 8) & 0xFF;
    audio_pkt[2] = flags;
    memcpy(&audio_pkt[3], data, len);

    struct bt_gatt_notify_params params = {
        .attr = &helix_attrs[AUDIO_ATTR_IDX],
        .data = audio_pkt,
        .len  = total,
    };

    return bt_gatt_notify_cb(current_conn, &params);
}

int transport_update_battery(uint8_t level, uint16_t millivolts)
{
    battery_packet[0] = level;
    battery_packet[1] = (uint8_t)(millivolts & 0xFF);
    battery_packet[2] = (uint8_t)((millivolts >> 8) & 0xFF);

    if (!is_connected || !current_conn) {
        return 0;
    }

    struct bt_gatt_notify_params params = {
        .attr = &helix_attrs[BATTERY_ATTR_IDX],
        .data = battery_packet,
        .len  = sizeof(battery_packet),
    };

    return bt_gatt_notify_cb(current_conn, &params);
}

bool transport_is_connected(void)
{
    return is_connected;
}

void transport_set_conn_callback(transport_conn_cb_t cb)
{
    conn_callback = cb;
}

void transport_set_mic_start(void (*fn)(void))
{
    mic_start_fn = fn;
}
```

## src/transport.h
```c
/*
 * Helix-Mic - BLE Transport Layer
 *
 * Dynamic GATT service with audio streaming and battery notifications.
 * Client drives link negotiation (MTU, PHY, DLE).
 */

#ifndef TRANSPORT_H
#define TRANSPORT_H

#include <zephyr/kernel.h>
#include <stdint.h>
#include <stddef.h>

/* Initialize BLE transport (enables BT, registers GATT service) */
int transport_init(void);

/* Start advertising */
int transport_start_advertising(void);

/* Send audio data notification */
int transport_send_audio(const uint8_t *data, size_t len, uint16_t seq, uint8_t flags);

/* Update battery state: percent (0-100, or 0xFF = unknown) + millivolts.
 * Sends a 3-byte notification [percent, mv_lo, mv_hi] if subscribed. */
int transport_update_battery(uint8_t level, uint16_t millivolts);

/* Check if a client is connected */
bool transport_is_connected(void);

/* Connection state callback type */
typedef void (*transport_conn_cb_t)(bool connected);
void transport_set_conn_callback(transport_conn_cb_t cb);

/* Set mic start function (called on connect for compatibility) */
void transport_set_mic_start(void (*fn)(void));

#endif /* TRANSPORT_H */
```
